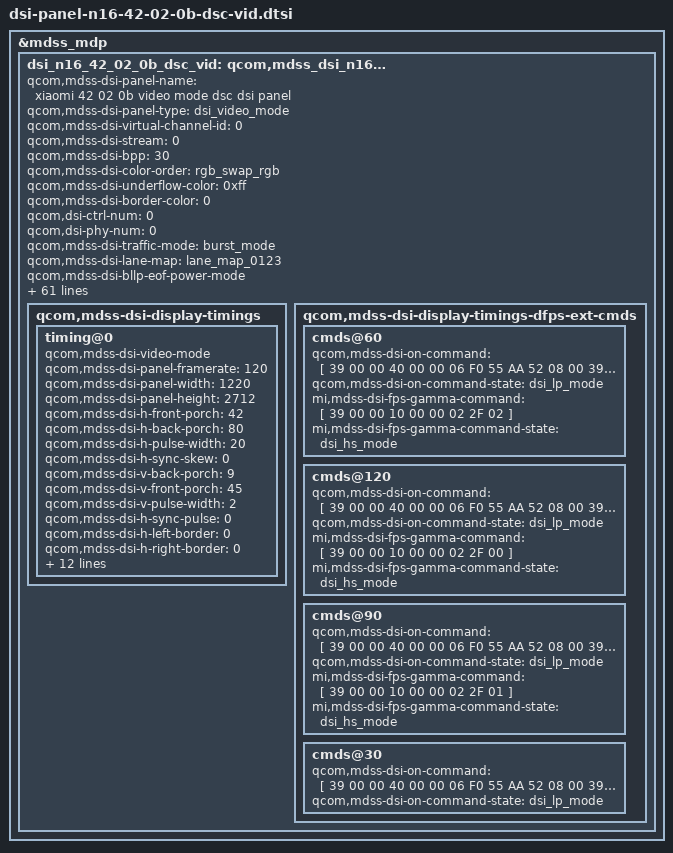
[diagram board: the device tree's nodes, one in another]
&mdss_mdp {
	dsi_n16_42_02_0b_dsc_vid: qcom,mdss_dsi_n16_42_02_0b_dsc_vid {
		qcom,mdss-dsi-panel-name = "xiaomi 42 02 0b video mode dsc dsi panel";
		qcom,mdss-dsi-panel-type = "dsi_video_mode";
		qcom,mdss-dsi-virtual-channel-id = <0>;
		qcom,mdss-dsi-stream = <0>;
		qcom,mdss-dsi-bpp = <30>;
		qcom,mdss-dsi-color-order = "rgb_swap_rgb";
		qcom,mdss-dsi-underflow-color = <0xff>;
		qcom,mdss-dsi-border-color = <0>;

		qcom,dsi-ctrl-num = <0>;
		qcom,dsi-phy-num = <0>;

		qcom,mdss-dsi-traffic-mode = "burst_mode";
		qcom,mdss-dsi-lane-map = "lane_map_0123";
		qcom,mdss-dsi-bllp-eof-power-mode;
		qcom,mdss-dsi-bllp-power-mode;
		qcom,mdss-dsi-lane-0-state;
		qcom,mdss-dsi-lane-1-state;
		qcom,mdss-dsi-lane-2-state;
		qcom,mdss-dsi-lane-3-state;
		qcom,mdss-dsi-dma-trigger = "trigger_sw";
		qcom,mdss-dsi-mdp-trigger = "none";
		qcom,mdss-dsi-reset-sequence =<1 11>, <0 1>, <1 11>;
		qcom,mdss-pan-physical-width-dimension = <695>;
		qcom,mdss-pan-physical-height-dimension = <1545>;

		qcom,mdss-dsi-tx-eot-append;
		qcom,mdss-dsi-lp11-init;
		qcom,mdss-dsi-bl-inverted-dbv;
		qcom,bl-update-flag = "delay_until_first_frame";

		qcom,mdss-dsi-panel-hdr-enabled;
		qcom,mdss-dsi-panel-hdr-color-primaries = <14500 15500 32000 17000 15500 30000 8000 3000>;
		qcom,mdss-dsi-panel-peak-brightness = <4200000>;
		qcom,mdss-dsi-panel-blackness-level = <3230>;

		qcom,mdss-dsi-pan-enable-dynamic-fps;
		qcom,mdss-dsi-pan-fps-update =
				"dfps_immediate_porch_mode_vfp";
		qcom,dsi-supported-dfps-list = <60 120 90 30>;

		mi,mdss-dsi-panel-cell-id-read-command = [06 01 00 02 00 00 01 DF];
		mi,mdss-dsi-panel-cell-id-read-pre-tx-command = [39 00 00 00 00 00 06 F0 55 AA 52 08 03];
		mi,mdss-dsi-panel-cell-id-read-pre-tx-command-state = "dsi_hs_mode";
		mi,mdss-dsi-panel-cell-id-read-command-state = "dsi_hs_mode";
		mi,mdss-dsi-panel-cell-id-read-length = <13>;

		mi,mdss-dsi-panel-wp-read-command = [06 01 00 02 00 00 01 A3];
		mi,mdss-dsi-panel-wp-read-command-state = "dsi_hs_mode";
		mi,mdss-dsi-panel-wp-read-length = <8>;

		mi,panel-build-id-read-needed;
		mi,panel-build-id-read-length = <1>;
		mi,mdss-dsi-panel-build-id-read-command = [06 01 00 02 00 00 01 DA];
		mi,mdss-dsi-panel-build-id-read-command-state = "dsi_hs_mode";

qcom,mdss-dsi-display-timings {
			timing@0{
				qcom,mdss-dsi-video-mode;
				qcom,mdss-dsi-panel-framerate = <120>;
				qcom,mdss-dsi-panel-width = <1220>;
				qcom,mdss-dsi-panel-height = <2712>;
				qcom,mdss-dsi-h-front-porch = <42>;
				qcom,mdss-dsi-h-back-porch = <80>;
				qcom,mdss-dsi-h-pulse-width = <20>;
				qcom,mdss-dsi-h-sync-skew = <0>;
				qcom,mdss-dsi-v-back-porch = <9>;
				qcom,mdss-dsi-v-front-porch = <45>;
				qcom,mdss-dsi-v-pulse-width = <2>;
				qcom,mdss-dsi-h-sync-pulse = <0>;
				qcom,mdss-dsi-h-left-border = <0>;
				qcom,mdss-dsi-h-right-border = <0>;
				qcom,mdss-dsi-v-top-border = <0>;
				qcom,mdss-dsi-v-bottom-border = <0>;

				qcom,compression-mode = "dsc";
				qcom,mdss-dsc-version = <0x12>;
				qcom,mdss-dsc-scr-version = <0x0>;
				qcom,mdss-dsc-slice-height = <12>;
				qcom,mdss-dsc-slice-width = <610>;
				qcom,mdss-dsc-slice-per-pkt = <2>;
				qcom,mdss-dsc-bit-per-component = <10>;
				qcom,mdss-dsc-bit-per-pixel = <8>;
				qcom,mdss-dsc-block-prediction-enable;
				qcom,mdss-dsi-panel-clockrate = <1098000000>;
			};
		};

qcom,mdss-dsi-display-timings-dfps-ext-cmds {
			cmds@60{
				qcom,mdss-dsi-on-command = [
					39 00 00 40 00 00 06 F0 55 AA 52 08 00
					39 00 00 40 00 00 02 6F 03
					39 00 00 40 00 00 02 C0 21
					//FPR_MODE = 0, FPR_ELVSS_EN = 1, FPR_ELVSS_DELAY = 1
					39 00 00 40 00 00 02 DF 09
					//FPR_EM_SWITCH_EN = 1, FPR_ALPHA_LUT_EN = 1
					39 00 00 40 00 00 02 6F 01
					39 00 00 40 00 00 02 DF 40
					//FPR_GMA_SEL[3:0] = 0, FPR_DGMA_SET_EN = 1, FPR_DGMA_SET_SEL[3:0] = 11
					39 00 00 40 00 00 02 6F 31
					39 00 00 40 00 00 03 DF 00 1A
					//FPR_ELVSS[7:0] = 47
					39 00 00 40 00 00 02 6F 34
					39 00 00 40 00 00 02 DF 23
					39 00 00 40 00 00 02 6F 2D
					39 00 00 40 00 00 06 C0 00 32 00 04 50
					39 00 00 40 00 00 02 6F 01
					39 00 00 40 00 00 02 C7 01
					39 00 00 40 00 00 06 F0 55 AA 52 08 01
					//FPR_VINITP1_EN = 0, FPR_VINITN1_EN = 1, FPR_VINITN2_EN = 0, FPR_VINITN3_EN = 0
					39 00 00 40 00 00 02 6F 2A
					39 00 00 40 00 00 02 B9 10
					//FPR_VINITN1 = (1A=-1.3V)
					39 00 00 40 00 00 02 6F 0C
					39 00 00 00 00 00 02 B9 1A
					39 00 00 40 00 00 02 6F 05
					39 00 00 40 00 00 03 E3 00 00
					39 00 00 40 00 00 02 6F 0A
					39 00 00 00 00 00 05 E3 00 00 00 00
					39 00 00 40 00 00 06 F0 55 AA 52 08 08
					39 00 00 40 00 00 02 6F CE
					39 00 00 40 00 00 02 BC 01
					39 00 00 40 00 00 02 6F CF
					39 00 00 00 00 00 09 BC 01 11 00 B6 01 11 00 44
					39 00 00 40 00 00 02 BE 03
					39 00 00 40 00 00 02 6F 0C
					39 00 00 00 00 00 09 E9 1D 36 0F D6 1C 51 0F AB
					39 00 00 00 00 00 06 88 81 02 61 09 85
					39 00 00 40 00 00 05 FF AA 55 A5 80
					39 00 00 40 00 00 02 6F 2A
					39 00 00 40 00 00 02 F4 08
					39 00 00 40 00 00 02 6F 46
					39 00 00 40 00 00 03 F4 07 09
					39 00 00 40 00 00 02 6F 4A
					39 00 00 40 00 00 03 F4 08 0A
					39 00 00 40 00 00 02 6F 56
					39 00 00 00 00 00 03 F4 44 44
					39 00 00 40 00 00 05 FF AA 55 A5 81
					39 00 00 40 00 00 02 6F 3C
					39 00 00 40 00 00 02 F5 84
					39 00 00 00 00 00 02 17 03
					39 00 00 40 00 00 02 71 00
					39 00 00 00 00 00 09 8D 00 00 04 C3 00 00 0A 97
					39 00 00 40 00 00 05 2A 00 00 04 C3
					39 00 00 40 00 00 05 2B 00 00 0A 97
					39 00 00 40 00 00 03 90 03 43
					39 00 00 40 00 00 13 91 AB A8 00 0C C2 00 02 32 01 31 00 08 08 BB 07 7B 10 F0
					39 00 00 40 00 00 0D 3B 00 0B 00 2D 00 0B 03 CD 00 0B 0A FD
					39 00 00 00 00 00 02 6F 10
					39 00 00 40 00 00 05 3B 00 0B 00 2D
					39 00 00 40 00 00 02 35 00
					39 00 00 40 00 00 02 6F 04
					39 00 00 40 00 00 03 51 00 00
					39 00 00 40 00 00 02 53 20
					39 00 00 40 00 00 02 57 00
					39 00 00 40 00 00 02 2F 02
					39 00 00 40 00 00 02 26 00
					39 00 00 00 00 00 03 5F 04 40
					/*ESD*/
					39 00 00 40 00 00 06 F0 55 AA 52 08 00
					39 00 00 40 00 00 03 BE 47 45
					39 00 00 40 00 00 02 6F 05
					39 00 00 00 00 00 02 BE 28
					39 00 00 40 00 00 02 6F 19
					39 00 00 40 00 00 05 BE 10 91 00 AB
					39 00 00 40 00 00 02 6F 0D
					39 00 00 00 00 00 02 D8 02
					/*SPR for P1.1*/
					39 00 00 00 00 00 06 F0 55 AA 52 08 07
					//SPR setting
					39 00 00 00 00 00 07 B0 8C C0 78 70 00 00
					39 00 00 00 00 00 07 B1 1C 0C 00 0C 1C 00
					//Index 0
					39 00 00 00 00 00 0A B2 28 28 28 28 28 28 28 28 28
					39 00 00 00 00 00 02 6F 36
					39 00 00 00 00 00 13 B2 32 32 32 32 32 32 32 32 32 0C 0C 0C 0C 0C 0C 0C 0C 0C
					//Index 1
					39 00 00 00 00 00 02 6F 09
					39 00 00 00 00 00 0A B2 28 28 28 28 28 28 28 28 28
					39 00 00 00 00 00 02 6F 48
					39 00 00 00 00 00 13 B2 32 32 32 32 32 32 32 32 32 0C 0C 0C 0C 0C 0C 0C 0C 0C
					//Index 3
					39 00 00 00 00 00 02 6F 1B
					39 00 00 00 00 00 0A B2 28 28 28 28 28 28 28 28 28
					39 00 00 00 00 00 02 6F 6C
					39 00 00 00 00 00 13 B2 32 32 32 32 32 32 32 32 32 0C 0C 0C 0C 0C 0C 0C 0C 0C
					//Index 4
					39 00 00 00 00 00 02 6F 24
					39 00 00 00 00 00 0A B2 28 28 28 28 28 28 28 28 28
					39 00 00 00 00 00 02 6F 7E
					39 00 00 00 00 00 13 B2 32 32 32 32 32 32 32 32 32 0C 0C 0C 0C 0C 0C 0C 0C 0C
					39 00 00 00 00 00 02 B3 6C
					/*video trim*/
					39 00 00 40 00 00 06 F0 55 AA 52 08 01
					39 00 00 40 00 00 02 EA 91
					39 00 00 40 00 00 02 6F 08
					39 00 00 40 00 00 02 EA 48
					39 00 00 40 00 00 02 6F 0B
					39 00 00 40 00 00 02 EA 91
					39 00 00 40 00 00 02 6F 13
					39 00 00 40 00 00 02 EA 72
					39 00 00 40 00 00 02 6F 04
					39 00 00 40 00 00 02 C3 0A
					39 00 00 40 00 00 02 6F 09
					39 00 00 00 00 00 02 C3 0A
					/*LVDT*/
					39 00 00 40 00 00 06 F0 55 AA 52 08 01
					39 00 00 40 00 00 02 6F 03
					39 00 00 00 00 00 02 C7 C7
					/*Delay 120ms*/
					39 00 00 00 78 00 02 11 00
					/* Display On */
					39 00 00 00 00 00 02 29 00
					/*120hz gain*/
					39 00 00 40 00 00 06 F0 55 AA 52 08 04
					39 00 00 40 00 00 02 CB 66
					//dbv0 8h
					39 00 00 40 00 00 06 DD 05 08 1F 3E 9B
					//dbv1 62h
					39 00 00 40 00 00 02 6F 05
					39 00 00 40 00 00 06 DD 05 08 1F 3E 9B
					//dbv2 147h
					39 00 00 40 00 00 02 6F 0A
					39 00 00 40 00 00 06 DD 05 08 1F 3E 9B
					//dbv3 4A3H
					39 00 00 40 00 00 02 6F 0F
					39 00 00 40 00 00 06 DD 05 08 1F 3E 9B
					//dbv4 7FF
					39 00 00 40 00 00 02 6F 14
					39 00 00 40 00 00 06 DD 05 08 1F 3E 9B
					//dbv5 FFF
					39 00 00 40 00 00 02 6F 19
					39 00 00 00 00 00 06 DD 05 08 1F 3E 9B
					39 00 00 40 00 00 02 6F 5A
					39 00 00 40 00 00 07 D2 10 10 10 10 10 14
					39 00 00 40 00 00 02 6F 60
					39 00 00 40 00 00 07 D2 10 10 10 10 10 0C
					39 00 00 40 00 00 02 6F 66
					39 00 00 40 00 00 07 D2 12 12 12 12 12 0C
					39 00 00 40 00 00 02 6F 6C
					39 00 00 40 00 00 07 D2 12 12 12 12 12 0A
					39 00 00 40 00 00 02 6F 72
					39 00 00 00 00 00 07 D2 12 12 12 12 12 08
					39 00 00 40 00 00 02 6F 78
					39 00 00 40 00 00 07 D2 28 28 28 28 28 14
					39 00 00 40 00 00 02 6F 7E
					39 00 00 40 00 00 07 D2 1A 1A 1A 1A 1A 10
					39 00 00 40 00 00 02 6F 84
					39 00 00 40 00 00 07 D2 1A 1A 1A 1A 1A 10
					39 00 00 40 00 00 02 6F 8A
					39 00 00 40 00 00 07 D2 1A 1A 1A 1A 1A 10
					39 00 00 40 00 00 02 6F 90
					39 00 00 00 00 00 07 D2 1A 1A 1A 1A 1A 08
					39 00 00 40 00 00 02 6F 96
					39 00 00 40 00 00 07 D2 14 14 14 14 14 10
					39 00 00 40 00 00 02 6F 9C
					39 00 00 40 00 00 07 D2 10 10 10 10 10 08
					39 00 00 40 00 00 02 6F A2
					39 00 00 40 00 00 07 D2 0D 0D 0D 0D 0D 08
					39 00 00 40 00 00 02 6F A8
					39 00 00 40 00 00 07 D2 0D 0D 0D 0D 0D 08
					39 00 00 40 00 00 02 6F AE
					39 00 00 00 00 00 07 D2 0B 0B 0B 0B 0B 08
					/*3D LUT*/
					39 00 00 00 00 00 06 F0 55 AA 52 08 00
					39 00 00 00 00 00 02 E6 80
					39 00 00 00 00 00 02 6F EA
					39 00 00 00 00 00 07 E8 10 10 20 00 00 00
					39 00 00 00 00 00 02 E6 81
					39 00 00 00 00 00 02 6F EA
					39 00 00 00 00 00 07 E8 10 10 20 00 00 00
					39 00 00 00 00 00 02 E6 82
					39 00 00 00 00 00 02 6F EA
					39 00 00 00 00 00 07 E8 10 10 20 00 00 00
					39 00 00 00 00 00 02 E6 83
					39 00 00 00 00 00 02 6F EA
					39 00 00 00 00 00 07 E8 10 10 20 00 00 00
					39 00 00 00 00 00 02 E6 84
					39 00 00 00 00 00 02 6F EA
					39 00 00 00 00 00 07 E8 10 10 20 00 00 00
					39 00 00 00 00 00 02 E6 85
					39 00 00 00 00 00 02 6F EA
					39 00 00 00 00 00 07 E8 10 10 20 00 00 00
					39 00 00 00 00 00 02 E6 86
					39 00 00 00 00 00 02 6F EA
					39 00 00 00 00 00 07 E8 10 10 20 00 00 00
					39 00 00 00 00 00 02 E6 87
					39 00 00 00 00 00 02 6F EA
					39 00 00 00 00 00 07 E8 10 10 20 00 00 00
					39 00 00 00 00 00 02 E6 88
					39 00 00 00 00 00 02 6F EA
					39 00 00 00 00 00 07 E8 10 10 20 00 00 00
					39 00 00 00 00 00 02 E6 00
				];
				qcom,mdss-dsi-on-command-state = "dsi_lp_mode";

				mi,mdss-dsi-fps-gamma-command = [
					39 00 00 10 00 00 02 2F 02
				];
				mi,mdss-dsi-fps-gamma-command-state = "dsi_hs_mode";

				#include "dsi-panel-n16-42-02-0b-dsc-vid-common.dtsi"
			};
			cmds@120{
				qcom,mdss-dsi-on-command = [
					39 00 00 40 00 00 06 F0 55 AA 52 08 00
					39 00 00 40 00 00 02 6F 03
					39 00 00 40 00 00 02 C0 21
					//FPR_MODE = 0, FPR_ELVSS_EN = 1, FPR_ELVSS_DELAY = 1
					39 00 00 40 00 00 02 DF 09
					//FPR_EM_SWITCH_EN = 1, FPR_ALPHA_LUT_EN = 1
					39 00 00 40 00 00 02 6F 01
					39 00 00 40 00 00 02 DF 40
					//FPR_GMA_SEL[3:0] = 0, FPR_DGMA_SET_EN = 1, FPR_DGMA_SET_SEL[3:0] = 11
					39 00 00 40 00 00 02 6F 31
					39 00 00 40 00 00 03 DF 00 1A
					//FPR_ELVSS[7:0] = 47
					39 00 00 40 00 00 02 6F 34
					39 00 00 40 00 00 02 DF 23
					39 00 00 40 00 00 02 6F 2D
					39 00 00 40 00 00 06 C0 00 32 00 04 50
					39 00 00 40 00 00 02 6F 01
					39 00 00 40 00 00 02 C7 01
					39 00 00 40 00 00 06 F0 55 AA 52 08 01
					//FPR_VINITP1_EN = 0, FPR_VINITN1_EN = 1, FPR_VINITN2_EN = 0, FPR_VINITN3_EN = 0
					39 00 00 40 00 00 02 6F 2A
					39 00 00 40 00 00 02 B9 10
					//FPR_VINITN1 = (1A=-1.3V)
					39 00 00 40 00 00 02 6F 0C
					39 00 00 00 00 00 02 B9 1A
					39 00 00 40 00 00 02 6F 05
					39 00 00 40 00 00 03 E3 00 00
					39 00 00 40 00 00 02 6F 0A
					39 00 00 00 00 00 05 E3 00 00 00 00
					39 00 00 40 00 00 06 F0 55 AA 52 08 08
					39 00 00 40 00 00 02 6F CE
					39 00 00 40 00 00 02 BC 01
					39 00 00 40 00 00 02 6F CF
					39 00 00 00 00 00 09 BC 01 11 00 B6 01 11 00 44
					39 00 00 40 00 00 02 BE 03
					39 00 00 40 00 00 02 6F 0C
					39 00 00 00 00 00 09 E9 1D 36 0F D6 1C 51 0F AB
					39 00 00 00 00 00 06 88 81 02 61 09 85
					39 00 00 40 00 00 05 FF AA 55 A5 80
					39 00 00 40 00 00 02 6F 2A
					39 00 00 40 00 00 02 F4 08
					39 00 00 40 00 00 02 6F 46
					39 00 00 40 00 00 03 F4 07 09
					39 00 00 40 00 00 02 6F 4A
					39 00 00 40 00 00 03 F4 08 0A
					39 00 00 40 00 00 02 6F 56
					39 00 00 00 00 00 03 F4 44 44
					39 00 00 40 00 00 05 FF AA 55 A5 81
					39 00 00 40 00 00 02 6F 3C
					39 00 00 40 00 00 02 F5 84
					39 00 00 00 00 00 02 17 03
					39 00 00 40 00 00 02 71 00
					39 00 00 00 00 00 09 8D 00 00 04 C3 00 00 0A 97
					39 00 00 40 00 00 05 2A 00 00 04 C3
					39 00 00 40 00 00 05 2B 00 00 0A 97
					39 00 00 40 00 00 03 90 03 43
					39 00 00 40 00 00 13 91 AB A8 00 0C C2 00 02 32 01 31 00 08 08 BB 07 7B 10 F0
					39 00 00 40 00 00 0D 3B 00 0B 00 2D 00 0B 03 CD 00 0B 0A FD
					39 00 00 00 00 00 02 6F 10
					39 00 00 40 00 00 05 3B 00 0B 00 2D
					39 00 00 40 00 00 02 35 00
					39 00 00 40 00 00 02 6F 04
					39 00 00 40 00 00 03 51 00 00
					39 00 00 40 00 00 02 53 20
					39 00 00 40 00 00 02 57 00
					39 00 00 40 00 00 02 2F 00
					39 00 00 40 00 00 02 26 00
					39 00 00 00 00 00 03 5F 04 40
					/*ESD*/
					39 00 00 40 00 00 06 F0 55 AA 52 08 00
					39 00 00 40 00 00 03 BE 47 45
					39 00 00 40 00 00 02 6F 05
					39 00 00 00 00 00 02 BE 28
					39 00 00 40 00 00 02 6F 19
					39 00 00 40 00 00 05 BE 10 91 00 AB
					39 00 00 40 00 00 02 6F 0D
					39 00 00 00 00 00 02 D8 02
					/*SPR for P1.1*/
					39 00 00 00 00 00 06 F0 55 AA 52 08 07
					//SPR setting
					39 00 00 00 00 00 07 B0 8C C0 78 70 00 00
					39 00 00 00 00 00 07 B1 1C 0C 00 0C 1C 00
					//Index 0
					39 00 00 00 00 00 0A B2 28 28 28 28 28 28 28 28 28
					39 00 00 00 00 00 02 6F 36
					39 00 00 00 00 00 13 B2 32 32 32 32 32 32 32 32 32 0C 0C 0C 0C 0C 0C 0C 0C 0C
					//Index 1
					39 00 00 00 00 00 02 6F 09
					39 00 00 00 00 00 0A B2 28 28 28 28 28 28 28 28 28
					39 00 00 00 00 00 02 6F 48
					39 00 00 00 00 00 13 B2 32 32 32 32 32 32 32 32 32 0C 0C 0C 0C 0C 0C 0C 0C 0C
					//Index 3
					39 00 00 00 00 00 02 6F 1B
					39 00 00 00 00 00 0A B2 28 28 28 28 28 28 28 28 28
					39 00 00 00 00 00 02 6F 6C
					39 00 00 00 00 00 13 B2 32 32 32 32 32 32 32 32 32 0C 0C 0C 0C 0C 0C 0C 0C 0C
					//Index 4
					39 00 00 00 00 00 02 6F 24
					39 00 00 00 00 00 0A B2 28 28 28 28 28 28 28 28 28
					39 00 00 00 00 00 02 6F 7E
					39 00 00 00 00 00 13 B2 32 32 32 32 32 32 32 32 32 0C 0C 0C 0C 0C 0C 0C 0C 0C
					39 00 00 00 00 00 02 B3 6C
					/*video trim*/
					39 00 00 40 00 00 06 F0 55 AA 52 08 01
					39 00 00 40 00 00 02 EA 91
					39 00 00 40 00 00 02 6F 08
					39 00 00 40 00 00 02 EA 48
					39 00 00 40 00 00 02 6F 0B
					39 00 00 40 00 00 02 EA 91
					39 00 00 40 00 00 02 6F 13
					39 00 00 40 00 00 02 EA 72
					39 00 00 40 00 00 02 6F 04
					39 00 00 40 00 00 02 C3 0A
					39 00 00 40 00 00 02 6F 09
					39 00 00 00 00 00 02 C3 0A
					/*LVDT*/
					39 00 00 40 00 00 06 F0 55 AA 52 08 01
					39 00 00 40 00 00 02 6F 03
					39 00 00 00 00 00 02 C7 C7
					/*Delay 120ms*/
					39 00 00 00 78 00 02 11 00
					/* Display On */
					39 00 00 00 00 00 02 29 00
					/*120hz gain*/
					39 00 00 40 00 00 06 F0 55 AA 52 08 04
					39 00 00 40 00 00 02 CB 66
					//dbv0 8h
					39 00 00 40 00 00 06 DD 05 08 1F 3E 9B
					//dbv1 62h
					39 00 00 40 00 00 02 6F 05
					39 00 00 40 00 00 06 DD 05 08 1F 3E 9B
					//dbv2 147h
					39 00 00 40 00 00 02 6F 0A
					39 00 00 40 00 00 06 DD 05 08 1F 3E 9B
					//dbv3 4A3H
					39 00 00 40 00 00 02 6F 0F
					39 00 00 40 00 00 06 DD 05 08 1F 3E 9B
					//dbv4 7FF
					39 00 00 40 00 00 02 6F 14
					39 00 00 40 00 00 06 DD 05 08 1F 3E 9B
					//dbv5 FFF
					39 00 00 40 00 00 02 6F 19
					39 00 00 00 00 00 06 DD 05 08 1F 3E 9B
					39 00 00 40 00 00 02 6F 5A
					39 00 00 40 00 00 07 D2 10 10 10 10 10 14
					39 00 00 40 00 00 02 6F 60
					39 00 00 40 00 00 07 D2 10 10 10 10 10 0C
					39 00 00 40 00 00 02 6F 66
					39 00 00 40 00 00 07 D2 12 12 12 12 12 0C
					39 00 00 40 00 00 02 6F 6C
					39 00 00 40 00 00 07 D2 12 12 12 12 12 0A
					39 00 00 40 00 00 02 6F 72
					39 00 00 00 00 00 07 D2 12 12 12 12 12 08
					39 00 00 40 00 00 02 6F 78
					39 00 00 40 00 00 07 D2 28 28 28 28 28 14
					39 00 00 40 00 00 02 6F 7E
					39 00 00 40 00 00 07 D2 1A 1A 1A 1A 1A 10
					39 00 00 40 00 00 02 6F 84
					39 00 00 40 00 00 07 D2 1A 1A 1A 1A 1A 10
					39 00 00 40 00 00 02 6F 8A
					39 00 00 40 00 00 07 D2 1A 1A 1A 1A 1A 10
					39 00 00 40 00 00 02 6F 90
					39 00 00 00 00 00 07 D2 1A 1A 1A 1A 1A 08
					39 00 00 40 00 00 02 6F 96
					39 00 00 40 00 00 07 D2 14 14 14 14 14 10
					39 00 00 40 00 00 02 6F 9C
					39 00 00 40 00 00 07 D2 10 10 10 10 10 08
					39 00 00 40 00 00 02 6F A2
					39 00 00 40 00 00 07 D2 0D 0D 0D 0D 0D 08
					39 00 00 40 00 00 02 6F A8
					39 00 00 40 00 00 07 D2 0D 0D 0D 0D 0D 08
					39 00 00 40 00 00 02 6F AE
					39 00 00 00 00 00 07 D2 0B 0B 0B 0B 0B 08
					/*3D LUT*/
					39 00 00 00 00 00 06 F0 55 AA 52 08 00
					39 00 00 00 00 00 02 E6 80
					39 00 00 00 00 00 02 6F EA
					39 00 00 00 00 00 07 E8 10 10 20 00 00 00
					39 00 00 00 00 00 02 E6 81
					39 00 00 00 00 00 02 6F EA
					39 00 00 00 00 00 07 E8 10 10 20 00 00 00
					39 00 00 00 00 00 02 E6 82
					39 00 00 00 00 00 02 6F EA
					39 00 00 00 00 00 07 E8 10 10 20 00 00 00
					39 00 00 00 00 00 02 E6 83
					39 00 00 00 00 00 02 6F EA
					39 00 00 00 00 00 07 E8 10 10 20 00 00 00
					39 00 00 00 00 00 02 E6 84
					39 00 00 00 00 00 02 6F EA
					39 00 00 00 00 00 07 E8 10 10 20 00 00 00
					39 00 00 00 00 00 02 E6 85
					39 00 00 00 00 00 02 6F EA
					39 00 00 00 00 00 07 E8 10 10 20 00 00 00
					39 00 00 00 00 00 02 E6 86
					39 00 00 00 00 00 02 6F EA
					39 00 00 00 00 00 07 E8 10 10 20 00 00 00
					39 00 00 00 00 00 02 E6 87
					39 00 00 00 00 00 02 6F EA
					39 00 00 00 00 00 07 E8 10 10 20 00 00 00
					39 00 00 00 00 00 02 E6 88
					39 00 00 00 00 00 02 6F EA
					39 00 00 00 00 00 07 E8 10 10 20 00 00 00
					39 00 00 00 00 00 02 E6 00
				];
				qcom,mdss-dsi-on-command-state = "dsi_lp_mode";

				mi,mdss-dsi-fps-gamma-command = [
					39 00 00 10 00 00 02 2F 00
				];
				mi,mdss-dsi-fps-gamma-command-state = "dsi_hs_mode";

				#include "dsi-panel-n16-42-02-0b-dsc-vid-common.dtsi"
			};
			cmds@90{
				qcom,mdss-dsi-on-command = [
					39 00 00 40 00 00 06 F0 55 AA 52 08 00
					39 00 00 40 00 00 02 6F 03
					39 00 00 40 00 00 02 C0 21
					//FPR_MODE = 0, FPR_ELVSS_EN = 1, FPR_ELVSS_DELAY = 1
					39 00 00 40 00 00 02 DF 09
					//FPR_EM_SWITCH_EN = 1, FPR_ALPHA_LUT_EN = 1
					39 00 00 40 00 00 02 6F 01
					39 00 00 40 00 00 02 DF 40
					//FPR_GMA_SEL[3:0] = 0, FPR_DGMA_SET_EN = 1, FPR_DGMA_SET_SEL[3:0] = 11
					39 00 00 40 00 00 02 6F 31
					39 00 00 40 00 00 03 DF 00 1A
					//FPR_ELVSS[7:0] = 47
					39 00 00 40 00 00 02 6F 34
					39 00 00 40 00 00 02 DF 23
					39 00 00 40 00 00 02 6F 2D
					39 00 00 40 00 00 06 C0 00 32 00 04 50
					39 00 00 40 00 00 02 6F 01
					39 00 00 40 00 00 02 C7 01
					39 00 00 40 00 00 06 F0 55 AA 52 08 01
					//FPR_VINITP1_EN = 0, FPR_VINITN1_EN = 1, FPR_VINITN2_EN = 0, FPR_VINITN3_EN = 0
					39 00 00 40 00 00 02 6F 2A
					39 00 00 40 00 00 02 B9 10
					//FPR_VINITN1 = (1A=-1.3V)
					39 00 00 40 00 00 02 6F 0C
					39 00 00 00 00 00 02 B9 1A
					39 00 00 40 00 00 02 6F 05
					39 00 00 40 00 00 03 E3 00 00
					39 00 00 40 00 00 02 6F 0A
					39 00 00 00 00 00 05 E3 00 00 00 00
					39 00 00 40 00 00 06 F0 55 AA 52 08 08
					39 00 00 40 00 00 02 6F CE
					39 00 00 40 00 00 02 BC 01
					39 00 00 40 00 00 02 6F CF
					39 00 00 00 00 00 09 BC 01 11 00 B6 01 11 00 44
					39 00 00 40 00 00 02 BE 03
					39 00 00 40 00 00 02 6F 0C
					39 00 00 00 00 00 09 E9 1D 36 0F D6 1C 51 0F AB
					39 00 00 00 00 00 06 88 81 02 61 09 85
					39 00 00 40 00 00 05 FF AA 55 A5 80
					39 00 00 40 00 00 02 6F 2A
					39 00 00 40 00 00 02 F4 08
					39 00 00 40 00 00 02 6F 46
					39 00 00 40 00 00 03 F4 07 09
					39 00 00 40 00 00 02 6F 4A
					39 00 00 40 00 00 03 F4 08 0A
					39 00 00 40 00 00 02 6F 56
					39 00 00 00 00 00 03 F4 44 44
					39 00 00 40 00 00 05 FF AA 55 A5 81
					39 00 00 40 00 00 02 6F 3C
					39 00 00 40 00 00 02 F5 84
					39 00 00 00 00 00 02 17 03
					39 00 00 40 00 00 02 71 00
					39 00 00 00 00 00 09 8D 00 00 04 C3 00 00 0A 97
					39 00 00 40 00 00 05 2A 00 00 04 C3
					39 00 00 40 00 00 05 2B 00 00 0A 97
					39 00 00 40 00 00 03 90 03 43
					39 00 00 40 00 00 13 91 AB A8 00 0C C2 00 02 32 01 31 00 08 08 BB 07 7B 10 F0
					39 00 00 40 00 00 0D 3B 00 0B 00 2D 00 0B 03 CD 00 0B 0A FD
					39 00 00 00 00 00 02 6F 10
					39 00 00 40 00 00 05 3B 00 0B 00 2D
					39 00 00 40 00 00 02 35 00
					39 00 00 40 00 00 02 6F 04
					39 00 00 40 00 00 03 51 00 00
					39 00 00 40 00 00 02 53 20
					39 00 00 40 00 00 02 57 00
					39 00 00 40 00 00 02 2F 01
					39 00 00 40 00 00 02 26 00
					39 00 00 00 00 00 03 5F 04 40
					/*ESD*/
					39 00 00 40 00 00 06 F0 55 AA 52 08 00
					39 00 00 40 00 00 03 BE 47 45
					39 00 00 40 00 00 02 6F 05
					39 00 00 00 00 00 02 BE 28
					39 00 00 40 00 00 02 6F 19
					39 00 00 40 00 00 05 BE 10 91 00 AB
					39 00 00 40 00 00 02 6F 0D
					39 00 00 00 00 00 02 D8 02
					/*SPR for P1.1*/
					39 00 00 00 00 00 06 F0 55 AA 52 08 07
					//SPR setting
					39 00 00 00 00 00 07 B0 8C C0 78 70 00 00
					39 00 00 00 00 00 07 B1 1C 0C 00 0C 1C 00
					//Index 0
					39 00 00 00 00 00 0A B2 28 28 28 28 28 28 28 28 28
					39 00 00 00 00 00 02 6F 36
					39 00 00 00 00 00 13 B2 32 32 32 32 32 32 32 32 32 0C 0C 0C 0C 0C 0C 0C 0C 0C
					//Index 1
					39 00 00 00 00 00 02 6F 09
					39 00 00 00 00 00 0A B2 28 28 28 28 28 28 28 28 28
					39 00 00 00 00 00 02 6F 48
					39 00 00 00 00 00 13 B2 32 32 32 32 32 32 32 32 32 0C 0C 0C 0C 0C 0C 0C 0C 0C
					//Index 3
					39 00 00 00 00 00 02 6F 1B
					39 00 00 00 00 00 0A B2 28 28 28 28 28 28 28 28 28
					39 00 00 00 00 00 02 6F 6C
					39 00 00 00 00 00 13 B2 32 32 32 32 32 32 32 32 32 0C 0C 0C 0C 0C 0C 0C 0C 0C
					//Index 4
					39 00 00 00 00 00 02 6F 24
					39 00 00 00 00 00 0A B2 28 28 28 28 28 28 28 28 28
					39 00 00 00 00 00 02 6F 7E
					39 00 00 00 00 00 13 B2 32 32 32 32 32 32 32 32 32 0C 0C 0C 0C 0C 0C 0C 0C 0C
					39 00 00 00 00 00 02 B3 6C
					/*video trim*/
					39 00 00 40 00 00 06 F0 55 AA 52 08 01
					39 00 00 40 00 00 02 EA 91
					39 00 00 40 00 00 02 6F 08
					39 00 00 40 00 00 02 EA 48
					39 00 00 40 00 00 02 6F 0B
					39 00 00 40 00 00 02 EA 91
					39 00 00 40 00 00 02 6F 13
					39 00 00 40 00 00 02 EA 72
					39 00 00 40 00 00 02 6F 04
					39 00 00 40 00 00 02 C3 0A
					39 00 00 40 00 00 02 6F 09
					39 00 00 00 00 00 02 C3 0A
					/*LVDT*/
					39 00 00 40 00 00 06 F0 55 AA 52 08 01
					39 00 00 40 00 00 02 6F 03
					39 00 00 00 00 00 02 C7 C7
					/*Delay 120ms*/
					39 00 00 00 78 00 02 11 00
					/* Display On */
					39 00 00 00 00 00 02 29 00
					/*120hz gain*/
					39 00 00 40 00 00 06 F0 55 AA 52 08 04
					39 00 00 40 00 00 02 CB 66
					//dbv0 8h
					39 00 00 40 00 00 06 DD 05 08 1F 3E 9B
					//dbv1 62h
					39 00 00 40 00 00 02 6F 05
					39 00 00 40 00 00 06 DD 05 08 1F 3E 9B
					//dbv2 147h
					39 00 00 40 00 00 02 6F 0A
					39 00 00 40 00 00 06 DD 05 08 1F 3E 9B
					//dbv3 4A3H
					39 00 00 40 00 00 02 6F 0F
					39 00 00 40 00 00 06 DD 05 08 1F 3E 9B
					//dbv4 7FF
					39 00 00 40 00 00 02 6F 14
					39 00 00 40 00 00 06 DD 05 08 1F 3E 9B
					//dbv5 FFF
					39 00 00 40 00 00 02 6F 19
					39 00 00 00 00 00 06 DD 05 08 1F 3E 9B
					39 00 00 40 00 00 02 6F 5A
					39 00 00 40 00 00 07 D2 10 10 10 10 10 14
					39 00 00 40 00 00 02 6F 60
					39 00 00 40 00 00 07 D2 10 10 10 10 10 0C
					39 00 00 40 00 00 02 6F 66
					39 00 00 40 00 00 07 D2 12 12 12 12 12 0C
					39 00 00 40 00 00 02 6F 6C
					39 00 00 40 00 00 07 D2 12 12 12 12 12 0A
					39 00 00 40 00 00 02 6F 72
					39 00 00 00 00 00 07 D2 12 12 12 12 12 08
					39 00 00 40 00 00 02 6F 78
					39 00 00 40 00 00 07 D2 28 28 28 28 28 14
					39 00 00 40 00 00 02 6F 7E
					39 00 00 40 00 00 07 D2 1A 1A 1A 1A 1A 10
					39 00 00 40 00 00 02 6F 84
					39 00 00 40 00 00 07 D2 1A 1A 1A 1A 1A 10
					39 00 00 40 00 00 02 6F 8A
					39 00 00 40 00 00 07 D2 1A 1A 1A 1A 1A 10
					39 00 00 40 00 00 02 6F 90
					39 00 00 00 00 00 07 D2 1A 1A 1A 1A 1A 08
					39 00 00 40 00 00 02 6F 96
					39 00 00 40 00 00 07 D2 14 14 14 14 14 10
					39 00 00 40 00 00 02 6F 9C
					39 00 00 40 00 00 07 D2 10 10 10 10 10 08
					39 00 00 40 00 00 02 6F A2
					39 00 00 40 00 00 07 D2 0D 0D 0D 0D 0D 08
					39 00 00 40 00 00 02 6F A8
					39 00 00 40 00 00 07 D2 0D 0D 0D 0D 0D 08
					39 00 00 40 00 00 02 6F AE
					39 00 00 00 00 00 07 D2 0B 0B 0B 0B 0B 08
					/*3D LUT*/
					39 00 00 00 00 00 06 F0 55 AA 52 08 00
					39 00 00 00 00 00 02 E6 80
					39 00 00 00 00 00 02 6F EA
					39 00 00 00 00 00 07 E8 10 10 20 00 00 00
					39 00 00 00 00 00 02 E6 81
					39 00 00 00 00 00 02 6F EA
					39 00 00 00 00 00 07 E8 10 10 20 00 00 00
					39 00 00 00 00 00 02 E6 82
					39 00 00 00 00 00 02 6F EA
					39 00 00 00 00 00 07 E8 10 10 20 00 00 00
					39 00 00 00 00 00 02 E6 83
					39 00 00 00 00 00 02 6F EA
					39 00 00 00 00 00 07 E8 10 10 20 00 00 00
					39 00 00 00 00 00 02 E6 84
					39 00 00 00 00 00 02 6F EA
					39 00 00 00 00 00 07 E8 10 10 20 00 00 00
					39 00 00 00 00 00 02 E6 85
					39 00 00 00 00 00 02 6F EA
					39 00 00 00 00 00 07 E8 10 10 20 00 00 00
					39 00 00 00 00 00 02 E6 86
					39 00 00 00 00 00 02 6F EA
					39 00 00 00 00 00 07 E8 10 10 20 00 00 00
					39 00 00 00 00 00 02 E6 87
					39 00 00 00 00 00 02 6F EA
					39 00 00 00 00 00 07 E8 10 10 20 00 00 00
					39 00 00 00 00 00 02 E6 88
					39 00 00 00 00 00 02 6F EA
					39 00 00 00 00 00 07 E8 10 10 20 00 00 00
					39 00 00 00 00 00 02 E6 00
				];
				qcom,mdss-dsi-on-command-state = "dsi_lp_mode";

				mi,mdss-dsi-fps-gamma-command = [
					39 00 00 10 00 00 02 2F 01
				];
				mi,mdss-dsi-fps-gamma-command-state = "dsi_hs_mode";

				#include "dsi-panel-n16-42-02-0b-dsc-vid-common.dtsi"
			};
			cmds@30{
				qcom,mdss-dsi-on-command = [
					39 00 00 40 00 00 06 F0 55 AA 52 08 00
					39 00 00 40 00 00 02 6F 03
					39 00 00 40 00 00 02 C0 21
					//FPR_MODE = 0, FPR_ELVSS_EN = 1, FPR_ELVSS_DELAY = 1
					39 00 00 40 00 00 02 DF 09
					//FPR_EM_SWITCH_EN = 1, FPR_ALPHA_LUT_EN = 1
					39 00 00 40 00 00 02 6F 01
					39 00 00 40 00 00 02 DF 40
					//FPR_GMA_SEL[3:0] = 0, FPR_DGMA_SET_EN = 1, FPR_DGMA_SET_SEL[3:0] = 11
					39 00 00 40 00 00 02 6F 31
					39 00 00 40 00 00 03 DF 00 1A
					//FPR_ELVSS[7:0] = 47
					39 00 00 40 00 00 02 6F 34
					39 00 00 40 00 00 02 DF 23
					39 00 00 40 00 00 02 6F 2D
					39 00 00 40 00 00 06 C0 00 32 00 04 50
					39 00 00 40 00 00 02 6F 01
					39 00 00 40 00 00 02 C7 01
					39 00 00 40 00 00 06 F0 55 AA 52 08 01
					//FPR_VINITP1_EN = 0, FPR_VINITN1_EN = 1, FPR_VINITN2_EN = 0, FPR_VINITN3_EN = 0
					39 00 00 40 00 00 02 6F 2A
					39 00 00 40 00 00 02 B9 10
					//FPR_VINITN1 = (1A=-1.3V)
					39 00 00 40 00 00 02 6F 0C
					39 00 00 00 00 00 02 B9 1A
					39 00 00 40 00 00 02 6F 05
					39 00 00 40 00 00 03 E3 00 00
					39 00 00 40 00 00 02 6F 0A
					39 00 00 00 00 00 05 E3 00 00 00 00
					39 00 00 40 00 00 06 F0 55 AA 52 08 08
					39 00 00 40 00 00 02 6F CE
					39 00 00 40 00 00 02 BC 01
					39 00 00 40 00 00 02 6F CF
					39 00 00 00 00 00 09 BC 01 11 00 B6 01 11 00 44
					39 00 00 40 00 00 02 BE 03
					39 00 00 40 00 00 02 6F 0C
					39 00 00 00 00 00 09 E9 1D 36 0F D6 1C 51 0F AB
					39 00 00 00 00 00 06 88 81 02 61 09 85
					39 00 00 40 00 00 05 FF AA 55 A5 80
					39 00 00 40 00 00 02 6F 2A
					39 00 00 40 00 00 02 F4 08
					39 00 00 40 00 00 02 6F 46
					39 00 00 40 00 00 03 F4 07 09
					39 00 00 40 00 00 02 6F 4A
					39 00 00 40 00 00 03 F4 08 0A
					39 00 00 40 00 00 02 6F 56
					39 00 00 00 00 00 03 F4 44 44
					39 00 00 40 00 00 05 FF AA 55 A5 81
					39 00 00 40 00 00 02 6F 3C
					39 00 00 40 00 00 02 F5 84
					39 00 00 00 00 00 02 17 03
					39 00 00 40 00 00 02 71 00
					39 00 00 00 00 00 09 8D 00 00 04 C3 00 00 0A 97
					39 00 00 40 00 00 05 2A 00 00 04 C3
					39 00 00 40 00 00 05 2B 00 00 0A 97
					39 00 00 40 00 00 03 90 03 43
					39 00 00 40 00 00 13 91 AB A8 00 0C C2 00 02 32 01 31 00 08 08 BB 07 7B 10 F0
					39 00 00 40 00 00 0D 3B 00 0B 00 2D 00 0B 03 CD 00 0B 0A FD
					39 00 00 00 00 00 02 6F 10
					39 00 00 40 00 00 05 3B 00 0B 00 2D
					39 00 00 40 00 00 02 35 00
					39 00 00 40 00 00 02 6F 04
					39 00 00 40 00 00 03 51 00 00
					39 00 00 40 00 00 02 53 20
					39 00 00 40 00 00 02 57 00
					39 00 00 40 00 00 02 2F 00
					39 00 00 40 00 00 02 26 00
					39 00 00 00 00 00 03 5F 04 40
					/*ESD*/
					39 00 00 40 00 00 06 F0 55 AA 52 08 00
					39 00 00 40 00 00 03 BE 47 45
					39 00 00 40 00 00 02 6F 05
					39 00 00 00 00 00 02 BE 28
					39 00 00 40 00 00 02 6F 19
					39 00 00 40 00 00 05 BE 10 91 00 AB
					39 00 00 40 00 00 02 6F 0D
					39 00 00 00 00 00 02 D8 02
					/*SPR for P1.1*/
					39 00 00 00 00 00 06 F0 55 AA 52 08 07
					//SPR setting
					39 00 00 00 00 00 07 B0 8C C0 78 70 00 00
					39 00 00 00 00 00 07 B1 1C 0C 00 0C 1C 00
					//Index 0
					39 00 00 00 00 00 0A B2 28 28 28 28 28 28 28 28 28
					39 00 00 00 00 00 02 6F 36
					39 00 00 00 00 00 13 B2 32 32 32 32 32 32 32 32 32 0C 0C 0C 0C 0C 0C 0C 0C 0C
					//Index 1
					39 00 00 00 00 00 02 6F 09
					39 00 00 00 00 00 0A B2 28 28 28 28 28 28 28 28 28
					39 00 00 00 00 00 02 6F 48
					39 00 00 00 00 00 13 B2 32 32 32 32 32 32 32 32 32 0C 0C 0C 0C 0C 0C 0C 0C 0C
					//Index 3
					39 00 00 00 00 00 02 6F 1B
					39 00 00 00 00 00 0A B2 28 28 28 28 28 28 28 28 28
					39 00 00 00 00 00 02 6F 6C
					39 00 00 00 00 00 13 B2 32 32 32 32 32 32 32 32 32 0C 0C 0C 0C 0C 0C 0C 0C 0C
					//Index 4
					39 00 00 00 00 00 02 6F 24
					39 00 00 00 00 00 0A B2 28 28 28 28 28 28 28 28 28
					39 00 00 00 00 00 02 6F 7E
					39 00 00 00 00 00 13 B2 32 32 32 32 32 32 32 32 32 0C 0C 0C 0C 0C 0C 0C 0C 0C
					39 00 00 00 00 00 02 B3 6C
					/*video trim*/
					39 00 00 40 00 00 06 F0 55 AA 52 08 01
					39 00 00 40 00 00 02 EA 91
					39 00 00 40 00 00 02 6F 08
					39 00 00 40 00 00 02 EA 48
					39 00 00 40 00 00 02 6F 0B
					39 00 00 40 00 00 02 EA 91
					39 00 00 40 00 00 02 6F 13
					39 00 00 40 00 00 02 EA 72
					39 00 00 40 00 00 02 6F 04
					39 00 00 40 00 00 02 C3 0A
					39 00 00 40 00 00 02 6F 09
					39 00 00 00 00 00 02 C3 0A
					/*LVDT*/
					39 00 00 40 00 00 06 F0 55 AA 52 08 01
					39 00 00 40 00 00 02 6F 03
					39 00 00 00 00 00 02 C7 C7
					/*Delay 120ms*/
					39 00 00 00 78 00 02 11 00
					/* Display On */
					39 00 00 00 00 00 02 29 00
					/*120hz gain*/
					39 00 00 40 00 00 06 F0 55 AA 52 08 04
					39 00 00 40 00 00 02 CB 66
					//dbv0 8h
					39 00 00 40 00 00 06 DD 05 08 1F 3E 9B
					//dbv1 62h
					39 00 00 40 00 00 02 6F 05
					39 00 00 40 00 00 06 DD 05 08 1F 3E 9B
					//dbv2 147h
					39 00 00 40 00 00 02 6F 0A
					39 00 00 40 00 00 06 DD 05 08 1F 3E 9B
					//dbv3 4A3H
					39 00 00 40 00 00 02 6F 0F
					39 00 00 40 00 00 06 DD 05 08 1F 3E 9B
					//dbv4 7FF
					39 00 00 40 00 00 02 6F 14
					39 00 00 40 00 00 06 DD 05 08 1F 3E 9B
					//dbv5 FFF
					39 00 00 40 00 00 02 6F 19
					39 00 00 00 00 00 06 DD 05 08 1F 3E 9B
					39 00 00 40 00 00 02 6F 5A
					39 00 00 40 00 00 07 D2 10 10 10 10 10 14
					39 00 00 40 00 00 02 6F 60
					39 00 00 40 00 00 07 D2 10 10 10 10 10 0C
					39 00 00 40 00 00 02 6F 66
					39 00 00 40 00 00 07 D2 12 12 12 12 12 0C
					39 00 00 40 00 00 02 6F 6C
					39 00 00 40 00 00 07 D2 12 12 12 12 12 0A
					39 00 00 40 00 00 02 6F 72
					39 00 00 00 00 00 07 D2 12 12 12 12 12 08
					39 00 00 40 00 00 02 6F 78
					39 00 00 40 00 00 07 D2 28 28 28 28 28 14
					39 00 00 40 00 00 02 6F 7E
					39 00 00 40 00 00 07 D2 1A 1A 1A 1A 1A 10
					39 00 00 40 00 00 02 6F 84
					39 00 00 40 00 00 07 D2 1A 1A 1A 1A 1A 10
					39 00 00 40 00 00 02 6F 8A
					39 00 00 40 00 00 07 D2 1A 1A 1A 1A 1A 10
					39 00 00 40 00 00 02 6F 90
					39 00 00 00 00 00 07 D2 1A 1A 1A 1A 1A 08
					39 00 00 40 00 00 02 6F 96
					39 00 00 40 00 00 07 D2 14 14 14 14 14 10
					39 00 00 40 00 00 02 6F 9C
					39 00 00 40 00 00 07 D2 10 10 10 10 10 08
					39 00 00 40 00 00 02 6F A2
					39 00 00 40 00 00 07 D2 0D 0D 0D 0D 0D 08
					39 00 00 40 00 00 02 6F A8
					39 00 00 40 00 00 07 D2 0D 0D 0D 0D 0D 08
					39 00 00 40 00 00 02 6F AE
					39 00 00 00 00 00 07 D2 0B 0B 0B 0B 0B 08
					/*3D LUT*/
					39 00 00 00 00 00 06 F0 55 AA 52 08 00
					39 00 00 00 00 00 02 E6 80
					39 00 00 00 00 00 02 6F EA
					39 00 00 00 00 00 07 E8 10 10 20 00 00 00
					39 00 00 00 00 00 02 E6 81
					39 00 00 00 00 00 02 6F EA
					39 00 00 00 00 00 07 E8 10 10 20 00 00 00
					39 00 00 00 00 00 02 E6 82
					39 00 00 00 00 00 02 6F EA
					39 00 00 00 00 00 07 E8 10 10 20 00 00 00
					39 00 00 00 00 00 02 E6 83
					39 00 00 00 00 00 02 6F EA
					39 00 00 00 00 00 07 E8 10 10 20 00 00 00
					39 00 00 00 00 00 02 E6 84
					39 00 00 00 00 00 02 6F EA
					39 00 00 00 00 00 07 E8 10 10 20 00 00 00
					39 00 00 00 00 00 02 E6 85
					39 00 00 00 00 00 02 6F EA
					39 00 00 00 00 00 07 E8 10 10 20 00 00 00
					39 00 00 00 00 00 02 E6 86
					39 00 00 00 00 00 02 6F EA
					39 00 00 00 00 00 07 E8 10 10 20 00 00 00
					39 00 00 00 00 00 02 E6 87
					39 00 00 00 00 00 02 6F EA
					39 00 00 00 00 00 07 E8 10 10 20 00 00 00
					39 00 00 00 00 00 02 E6 88
					39 00 00 00 00 00 02 6F EA
					39 00 00 00 00 00 07 E8 10 10 20 00 00 00
					39 00 00 00 00 00 02 E6 00
				];
				qcom,mdss-dsi-on-command-state = "dsi_lp_mode";

				#include "dsi-panel-n16-42-02-0b-dsc-vid-common.dtsi"
			};
		};
	};
};

&dsi_n16_42_02_0b_dsc_vid {
	mi,panel-id = <0x004e3136 0x00420201>;

	mi,max-brightness-clone = <16383>;
	mi,normal-max-brightness-clone = <4095>;
	mi,mdss-dsi-fac-bl-max-level = <2047>;
	mi,mdss-fac-brightness-max-level = <2047>;

	/* IRQF_ONESHOT | IRQF_TRIGGER_HIGH */
	mi,esd-err-irq-gpio = <&tlmm 65 0x2004>;
	mi,panel-ignore-esd-in-aod;

	mi,thermal-dimming-flag;
	mi,panel-on-dimming-delay = <120>;
	mi,dimming-need-update-speed;
	mi,dimming-node = <0 200 450 800 4095>;

	mi,doze-hbm-dbv-level = <245>;
	mi,doze-lbm-dbv-level = <20>;
	mi,ddic-round-corner-enabled;

	//use fps cmdsets
	mi,video-fps-cmdsets-flag;
	mi,local-hbm-enabled;
	mi,need-fod-animal-in-normal-enabled;
	mi,local-hbm-ui-ready-delay-num-frame = <3>; /* 3 frame */
};
